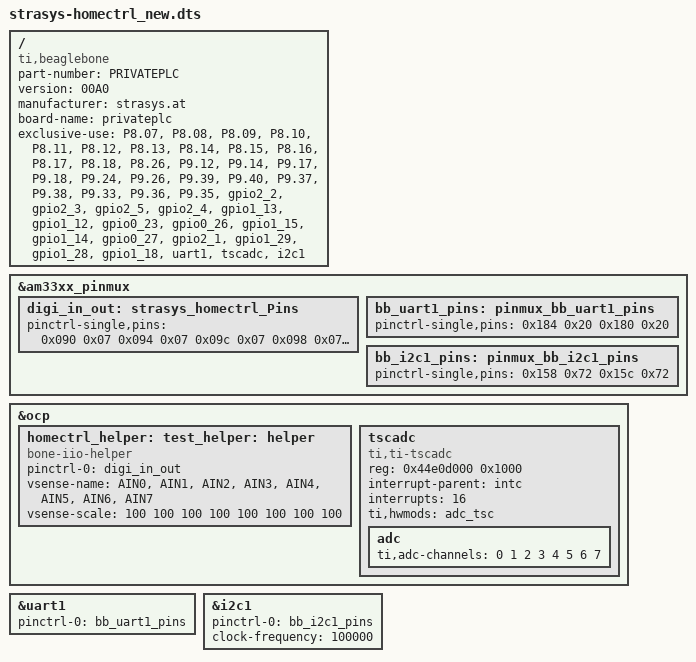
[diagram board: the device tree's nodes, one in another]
/*  
* Copyright (C) 2012 Texas Instruments Incorporated - http://www.ti.com/
*
* This program is free software; you can redistribute it and/or modify
* it under the terms of the GNU General Purpose License Version 2 as
* published by the Free Software Foundation
*
*Device tree description of home - controller 
*Idea and development
*strasys.at
*Dipl.-Ing. Johannes Strasser
*January 2014
*modified: 13th of January 2016
*/

/dts-v1/;
/plugin/;

/{
       compatible = "ti,beaglebone", "ti,beaglebone-black";
       part-number = "PRIVATEPLC";
       version = "00A0";
       manufacturer = "strasys.at";
       board-name = "privateplc";
       
       /* state the resources this cape uses */
	exclusive-use =
		/* the pin header uses */
		"P8.07",	/* digiout: gpio2_2 */
		"P8.08",	/* digiout: gpio2_3 */
		"P8.09",	/* digiout: gpio2_5 */
		"P8.10",	/* digiout: gpio2_4 */
		"P8.11",	/* digiout: gpio1_13 */
		"P8.12",	/* digiout: gpio1_12 */
		"P8.13",	/* digiout: gpio0_23 */
		"P8.14",	/* digiout: gpio0_26 */
		"P8.15",	/* digiin:  gpio1_15 */
		"P8.16",	/* digiin:  gpio1_14 */
		"P8.17",	/* digiin:  gpio0_27 */
		"P8.18",	/* digiin:  gpio2_1 */
		"P8.26",	/* digiin:  gpio1_29 */
		"P9.12",	/* digiout:	gpio1_28 */
		"P9.14",	/* digiin:  gpio1_18 */
		"P9.17",	/* I2C1_SCL */
		"P9.18",	/* I2C1_SDA */
		"P9.24",	/* TTL-TXD_4D: uart1_txd */
		"P9.26",	/* TTL-TXD_4D: uart1_rxd */
		"P9.39",	/* AIN0 */
		"P9.40",	/* AIN1 */
		"P9.37",	/* AIN2 */
		"P9.38",	/* AIN3 */
		"P9.33",	/* AIN4 */
		"P9.36",	/* AIN5 */
		"P9.35",	/* AIN6 */
		/* the hardware IP uses */
		"gpio2_2",
		"gpio2_3",
		"gpio2_5",
		"gpio2_4",
		"gpio1_13",
		"gpio1_12",
		"gpio0_23",
		"gpio0_26",
		"gpio1_15",
		"gpio1_14",
		"gpio0_27",
		"gpio2_1",
		"gpio1_29",
		"gpio1_28",
		"gpio1_18",
		"uart1",
		"tscadc",
		"i2c1";

       fragment@0 {
             target = <&am33xx_pinmux>;
            
             __overlay__ {
                  digi_in_out: strasys_homectrl_Pins {
			pinctrl-single,pins = <
				0x090 0x07 /* P8_07 66 OUTPUT MODE7 */
				0x094 0x07 /* P8_08 67 OUTPUT MODE7 */
				0x09c 0x07 /* P8_09 69 OUTPUT MODE7 */
				0x098 0x07 /* P8_10 68 OUTPUT MODE7 */
				0x034 0x07 /* P8_11 45 OUTPUT MODE7 */
				0x030 0x07 /* P8_12 44 OUTPUT MODE7 */
				0x024 0x07 /* P8_13 23 OUTPUT MODE7 */
				0x028 0x07 /* P8_14 26 OUTPUT MODE7 */
				0x03c 0x27 /* P8_15 47 INPUT MODE7 */
				0x038 0x27 /* P8_16 46 INPUT MODE7 */
				0x02c 0x27 /* P8_17 27 INPUT MODE7 */
				0x08c 0x27 /* P8_18 65 INPUT MODE7 */
				0x07c 0x27 /* P8_26 61 INPUT MODE7 */
				0x078 0x07 /* P9_12 60 OUTPUT MODE7 */
				0x048 0x27 /* P9_14 50 INPUT MODE7 */ 
          				
                   /* OUTPUT  GPIO(mode7) 0x07 pulldown, 0x17 pullup, 0x?f no pullup/down */
			       /* INPUT   GPIO(mode7) 0x27 pulldown, 0x37 pullup, 0x?f no pullup/down */

			>;
			};
            };
       		};

       fragment@1 {
		target = <&ocp>;
		__overlay__ {
		
			homectrl_helper: helper {
				compatible = "bone-pinmux-helper";
				pinctrl-names = "default";
				pinctrl-0 = <&digi_in_out>;
				status = "okay";
			};
		};
	};
	
	fragment@11 {
		target = <&am33xx_pinmux>;
		__overlay__ {
			bb_uart1_pins: pinmux_bb_uart1_pins {
				pinctrl-single,pins = <
					0x184 0x20	/* P9.24 uart1_txd.uart1_txd | MODE0 */
					0x180 0x20	/* P9.26 uart1_rxd.uart1_rxd | MODE0 */
				>;
			};
		};
	};

	fragment@12 {
		target = <&uart1>;	/* really uart1 */
		__overlay__ {
			status = "okay";
			pinctrl-names = "default";
			pinctrl-0 = <&bb_uart1_pins>;
		};
	};

	fragment@20 {
		target = <&am33xx_pinmux>;
		__overlay__ {
			bb_i2c1_pins: pinmux_bb_i2c1_pins {
				pinctrl-single,pins = <
					0x158 0x72	/* spi0_d1.i2c1_sda, SLEWCTRL_SLOW | INPUT_PULLUP | MODE2 */
					0x15c 0x72	/* spi0_cs0.i2c1_scl, SLEWCTRL_SLOW | INPUT_PULLUP | MODE2 */
				>;
			};
		};
	};
	
	fragment@21 {
		target = <&i2c1>;	/* i2c1 is numbered correctly */
		__overlay__ {
			status = "okay";
			pinctrl-names = "default";
			pinctrl-0 = <&bb_i2c1_pins>;

			/* this is the configuration part */
			clock-frequency = <100000>;

			#address-cells = <1>;
			#size-cells = <0>;

			/* add any i2c devices on the bus here */

			// commented out example of a touchscreen (taken from BB-BONE-LCD7-01-00A4) */
			// maxtouch@4a {
			//	compatible = "mXT224";
			//	reg = <0x4a>;
			//	interrupt-parent = <&gpio4>;
			//	interrupts = <19 0x0>;
			//	atmel,irq-gpio = <&gpio4 19 0>;
			// };
		};
	};
	
	fragment@30 {
		target = <&ocp>;
		__overlay__ {
			/* avoid stupid warning */
			#address-cells = <1>;
			#size-cells = <1>;

			tscadc {
				compatible = "ti,ti-tscadc";
				reg = <0x44e0d000 0x1000>;
				interrupt-parent = <&intc>;
				interrupts = <16>;
				ti,hwmods = "adc_tsc";
				status = "okay";

				adc {
					ti,adc-channels = <0 1 2 3 4 5 6 7>;
				};
			};

			test_helper: helper {
				compatible = "bone-iio-helper";
				vsense-name  = "AIN0", "AIN1", "AIN2", "AIN3", "AIN4", "AIN5", "AIN6", "AIN7";
				vsense-scale = <100     100     100     100     100     100     100     100>;
				status = "okay";
			};
		};
	};


}; /* root node end */

	


